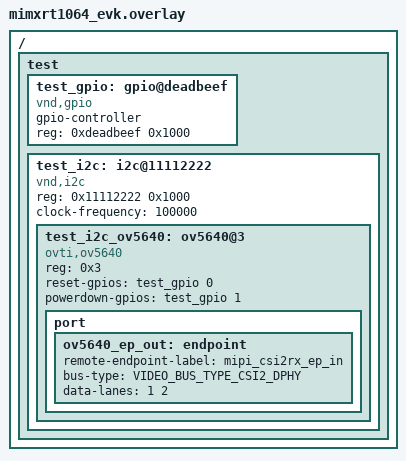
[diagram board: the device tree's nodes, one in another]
/*
 * Copyright 2024 NXP
 * Copyright (c) 2024, Charles Dias <charlesdias.cd@outlook.com>
 *
 * SPDX-License-Identifier: Apache-2.0
 *
 * Names in this file should be chosen in a way that won't conflict
 * with real-world devicetree nodes, to allow these tests to run on
 * (and be extended to test) real hardware.
 */

#include <zephyr/dt-bindings/video/video-interfaces.h>

/ {
	test {
		#address-cells = <1>;
		#size-cells = <1>;

		test_gpio: gpio@deadbeef {
			compatible = "vnd,gpio";
			gpio-controller;
			reg = <0xdeadbeef 0x1000>;
			#gpio-cells = <0x2>;
			status = "okay";
		};

		test_i2c: i2c@11112222 {
			#address-cells = <1>;
			#size-cells = <0>;
			compatible = "vnd,i2c";
			reg = <0x11112222 0x1000>;
			status = "okay";
			clock-frequency = <100000>;

			test_i2c_ov5640: ov5640@3 {
				compatible = "ovti,ov5640";
				reg = <0x3>;
				reset-gpios = <&test_gpio 0 0>;
				powerdown-gpios = <&test_gpio 1 0>;

				port {
					ov5640_ep_out: endpoint {
						remote-endpoint-label = "mipi_csi2rx_ep_in";
						bus-type = <VIDEO_BUS_TYPE_CSI2_DPHY>;
						data-lanes = <1 2>;
					};
				};
			};
		};
	};
};
